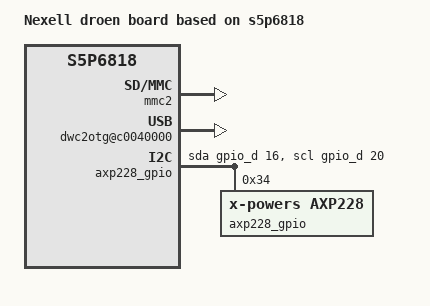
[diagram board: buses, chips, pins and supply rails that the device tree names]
/*
 * (C) Copyright 2016 Nexell
 * Youngbok, Park <park@nexell.co.kr>
 *
 * SPDX-License-Identifier:      GPL-2.0+
 */

/dts-v1/;
#include "s5p6818.dtsi"
#include "s5p6818-drone_ref-axp228.dtsi"

/ {
	model = "Nexell droen  board based on s5p6818";
	cpu-model = "S5p6818";

	compatible = "nexell,s5p6818";

	mmc2:mmc@c0069000 {
		nexell,drive_dly = <0x0>;
		nexell,drive_shift = <0x03>;
		nexell,sample_dly = <0x00>;
		nexell,sample_shift = <0x02>;
		frequency = <50000000>;
		nexell,ddr = <1>;
		status = "okay";
	};

	mmc0:mmc@c0062000 {
		frequency = <50000000>;
		nexell,drive_dly = <0x0>;
		nexell,drive_shift = <0x03>;
		nexell,sample_dly = <0x00>;
		nexell,sample_shift = <0x02>;
		status = "disabled";
	};


	dwc2otg@c0040000 {
		status = "okay";
	};

	axp228_gpio:i2c_gpio@0 {
		compatible = "i2c-gpio";
		#address-cells = <1>;
		#size-cells = <0>;
		gpios = <&gpio_d 16 1>,	/* SDA */
		      <&gpio_d 20 1>;	/* SCL */

		i2c-gpio,delay-us = <3>;
		axp228_gpio@34 {
			compatible = "x-powers,axp228";
			reg = <0x34>;
		};
	};
};
